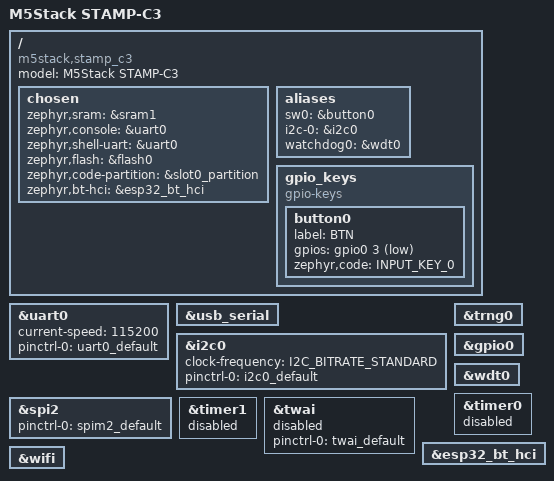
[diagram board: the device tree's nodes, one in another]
/*
 * Copyright 2022 TOKITA Hiroshi <tokita.hiroshi@fujitsu.com>
 *
 * SPDX-License-Identifier: Apache-2.0
 */

/dts-v1/;

#include <espressif/esp32c3/esp32c3_fx4.dtsi>
#include "stamp_c3-pinctrl.dtsi"
#include <zephyr/dt-bindings/input/input-event-codes.h>
#include <espressif/partitions_0x0_default.dtsi>

/ {
	model = "M5Stack STAMP-C3";
	compatible = "m5stack,stamp_c3";

	chosen {
		zephyr,sram = &sram1;
		zephyr,console = &uart0;
		zephyr,shell-uart = &uart0;
		zephyr,flash = &flash0;
		zephyr,code-partition = &slot0_partition;
		zephyr,bt-hci = &esp32_bt_hci;
	};

	aliases {
		sw0 = &button0;
		i2c-0 = &i2c0;
		watchdog0 = &wdt0;
	};

	gpio_keys {
		compatible = "gpio-keys";

		button0: button0 {
			label = "BTN";
			gpios = <&gpio0 3 (GPIO_PULL_UP | GPIO_ACTIVE_LOW)>;
			zephyr,code = <INPUT_KEY_0>;
		};
	};
};

&uart0 {
	status = "okay";
	current-speed = <115200>;
	pinctrl-0 = <&uart0_default>;
	pinctrl-names = "default";
};

&usb_serial {
	status = "okay";
};

&i2c0 {
	status = "okay";
	clock-frequency = <I2C_BITRATE_STANDARD>;
	pinctrl-0 = <&i2c0_default>;
	pinctrl-names = "default";
};

&trng0 {
	status = "okay";
};

&spi2 {
	#address-cells = <1>;
	#size-cells = <0>;
	status = "okay";
	pinctrl-0 = <&spim2_default>;
	pinctrl-names = "default";
};

&gpio0 {
	status = "okay";
};

&wdt0 {
	status = "okay";
};

&timer0 {
	status = "disabled";
};

&timer1 {
	status = "disabled";
};

&twai {
	/* requires external CAN transceiver or jumper on RX and TX pins for loopback testing */
	status = "disabled";
	pinctrl-0 = <&twai_default>;
	pinctrl-names = "default";
};

&esp32_bt_hci {
	status = "okay";
};

&wifi {
	status = "okay";
};
